# ATSAM3SD8B register map
Vendor: Atmel; File version: 0
CPU: CM3 r2p0, selectable endian, no MPU, no FPU, 0x4 interrupt priority bits, 0x0 interrupts
Registers are 32-bit, read-write, no defined reset value unless marked. A register's access mark holds for its fields unless they carry their own. Offsets are from the block's base; [hi:lo] are bit positions; {n}, {i} and the like mark numbered series; 'fields as' and 'values as' point back to an identical list.

## CRCCU — Cyclic Redundancy Check Calculation Unit
Base 0x40044000; register names take the prefix CRCCU_
0x00 DSCR reset 0x0 — CRCCU Descriptor Base Register
  [31:9] DSCR — Descriptor Base Address
0x08 DMA_EN wo reset 0x0 — CRCCU DMA Enable Register
  [0] DMAEN — DMA Enable Register
0x0C DMA_DIS wo reset 0x0 — CRCCU DMA Disable Register
  [0] DMADIS — DMA Disable Register
0x10 DMA_SR ro reset 0x0 — CRCCU DMA Status Register
  [0] DMASR — DMA Status Register
0x14 DMA_IER wo reset 0x0 — CRCCU DMA Interrupt Enable Register
  [0] DMAIER — Interrupt Enable register
0x18 DMA_IDR wo reset 0x0 — CRCCU DMA Interrupt Disable Register
  [0] DMAIDR — Interrupt Disable register
0x1C DMA_IMR ro reset 0x0 — CRCCU DMA Interrupt Mask Register
  [0] DMAIMR — Interrupt Mask Register
0x20 DMA_ISR ro reset 0x0 — CRCCU DMA Interrupt Status Register
  [0] DMAISR — Interrupt Status register
0x34 CR wo reset 0x0 — CRCCU Control Register
  [0] RESET — CRC Computation Reset
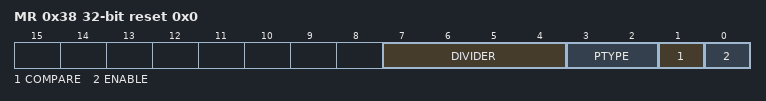
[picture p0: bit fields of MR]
0x38 MR reset 0x0 — CRCCU Mode Register
  [7:4] DIVIDER — Request Divider
  [3:2] PTYPE — Primitive Polynomial
    0=CCITT8023 (Polynom 0x04C11DB7); 1=CASTAGNOLI (Polynom 0x1EDC6F41); 2=CCITT16 (Polynom 0x1021)
  [1] COMPARE — CRC Compare
  [0] ENABLE — CRC Enable
0x3C SR ro reset 0xFFFFFFFF — CRCCU Status Register
  [31:0] CRC — Cyclic Redundancy Check Value
0x40 IER wo reset 0x0 — CRCCU Interrupt Enable Register
  [0] ERRIER — CRC Error Interrupt Enable
0x44 IDR wo reset 0x0 — CRCCU Interrupt Disable Register
  [0] ERRIDR — CRC Error Interrupt Disable
0x48 IMR ro reset 0x0 — CRCCU Interrupt Mask Register
  [0] ERRIMR — CRC Error Interrupt Mask
0x4C ISR ro reset 0x0 — CRCCU Interrupt Status Register
  [0] ERRISR — CRC Error Interrupt Status

## MATRIX — AHB Bus Matrix
Base 0x400E0200
{0x0+4i} MATRIX_MCFG[{i}] (i=0..3) — Master Configuration Register
  [2:0] ULBT — Undefined Length Burst Type
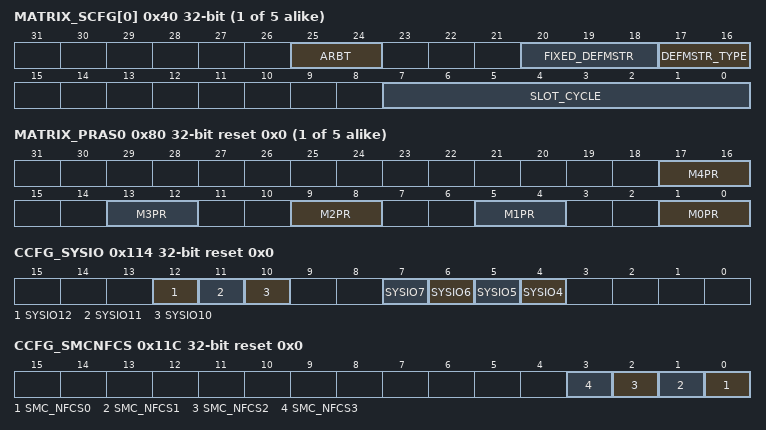
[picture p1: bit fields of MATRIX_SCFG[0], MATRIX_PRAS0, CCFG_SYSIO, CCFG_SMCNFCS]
{0x40+4i} MATRIX_SCFG[{i}] (i=0..4) — Slave Configuration Register
  [25:24] ARBT — Arbitration Type
  [20:18] FIXED_DEFMSTR — Fixed Default Master
  [17:16] DEFMSTR_TYPE — Default Master Type
  [7:0] SLOT_CYCLE — Maximum Number of Allowed Cycles for a Burst
{0x80+8i} MATRIX_PRAS{i} reset 0x0 (i=0..4) — Priority Register A for Slave {i}
  [4n+1:4n] M{n}PR (n=0..4) — Master {n} Priority
0x114 CCFG_SYSIO reset 0x0 — System I/O Configuration register
  [12] SYSIO12 — PB12 or ERASE Assignment
  [11] SYSIO11 — PB11 or DDP Assignment
  [10] SYSIO10 — PB10 or DDM Assignment
  [7] SYSIO7 — PB7 or TCK/SWCLK Assignment
  [6] SYSIO6 — PB6 or TMS/SWDIO Assignment
  [5] SYSIO5 — PB5 or TDO/TRACESWO Assignment
  [4] SYSIO4 — PB4 or TDI Assignment
0x11C CCFG_SMCNFCS reset 0x0 — SMC Chip Select NAND Flash Assignment Register
  [n] SMC_NFCS{n} (n=0..3) — SMC NAND Flash Chip Select {n} Assignment
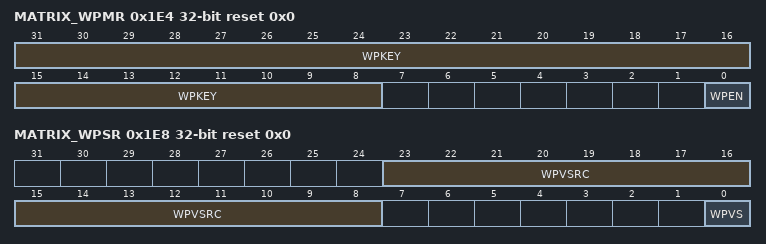
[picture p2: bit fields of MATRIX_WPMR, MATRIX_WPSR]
0x1E4 MATRIX_WPMR reset 0x0 — Write Protect Mode Register
  [31:8] WPKEY — Write Protect KEY (Write-only)
  [0] WPEN — Write Protect ENable
0x1E8 MATRIX_WPSR ro reset 0x0 — Write Protect Status Register
  [23:8] WPVSRC — Write Protect Violation Source
  [0] WPVS — Write Protect Violation Status

## CHIPID — Chip Identifier
Base 0x400E0740; register names take the prefix CHIPID_
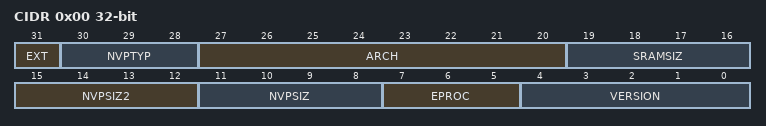
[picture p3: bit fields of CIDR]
0x00 CIDR ro — Chip ID Register
  [31] EXT — Extension Flag
  [30:28] NVPTYP — Nonvolatile Program Memory Type
    0=ROM; 1=ROMLESS (ROMless or on-chip Flash); 2=FLASH (Embedded Flash Memory); 3=ROM_FLASH (ROM and Embedded Flash MemoryNVPSIZ is ROM size NVPSIZ2 is Flash size); 4=SRAM (SRAM emulating ROM)
  [27:20] ARCH — Architecture Identifier
    25=AT91SAM9xx Series; 41=AT91SAM9XExx Series; 52=AT91x34 Series; 55=CAP7 (CAP7 Series); 57=CAP9 (CAP9 Series); 59=CAP11 (CAP11 Series); 64=AT91x40 Series; 66=AT91x42 Series; 85=AT91x55 Series; 96=AT91SAM7Axx Series; 97=AT91SAM7AQxx Series; 99=AT91x63 Series; 112=AT91SAM7Sxx Series; 113=AT91SAM7XCxx Series; 114=AT91SAM7SExx Series; 115=AT91SAM7Lxx Series; 117=AT91SAM7Xxx Series; 118=AT91SAM7SLxx Series; 128=SAM3UxC Series (100-pin version); 129=SAM3UxE Series (144-pin version); 131=SAM3AxC Series (100-pin version); 131=SAM4AxC Series (100-pin version); 132=SAM3XxC Series (100-pin version); 132=SAM4XxC Series (100-pin version); 133=SAM3XxE Series (144-pin version); 133=SAM4XxE Series (144-pin version); 134=SAM3XxG Series (208/217-pin version); 134=SAM4XxG Series (208/217-pin version); 136=SAM3SxASeries (48-pin version); 136=SAM4SxA Series (48-pin version); 137=SAM3SxB Series (64-pin version); 137=SAM4SxB Series (64-pin version); 138=SAM3SxC Series (100-pin version); 138=SAM4SxC Series (100-pin version); 146=AT91x92 Series; 147=SAM3NxA Series (48-pin version); 148=SAM3NxB Series (64-pin version); 149=SAM3NxC Series (100-pin version); 153=SAM3SDxB Series (64-pin version); 154=SAM3SDxC Series (100-pin version); 165=SAM5A; 240=AT75Cxx Series
  [19:16] SRAMSIZ — Internal SRAM Size
    0=48K (48K bytes); 1=1K (1K bytes); 2=2K (2K bytes); 3=6K (6K bytes); 4=24K (24K bytes); 5=4K (4K bytes); 6=80K (80K bytes); 7=160K (160K bytes); 8=8K (8K bytes); 9=16K (16K bytes); 10=32K (32K bytes); 11=64K (64K bytes); 12=128K (128K bytes); 13=256K (256K bytes); 14=96K (96K bytes); 15=512K (512K bytes)
  [15:12] NVPSIZ2 — Second Nonvolatile Program Memory Size
    0=NONE; 1=8K (8K bytes); 2=16K (16K bytes); 3=32K (32K bytes); 5=64K (64K bytes); 7=128K (128K bytes); 9=256K (256K bytes); 10=512K (512K bytes); 12=1024K (1024K bytes); 14=2048K (2048K bytes)
  [11:8] NVPSIZ — Nonvolatile Program Memory Size
    values as NVPSIZ2
  [7:5] EPROC — Embedded Processor
    1=ARM946ES; 2=ARM7TDMI; 3=CM3 (Cortex-M3); 4=ARM920T; 5=ARM926EJS; 6=CA5 (Cortex-A5); 7=CM4 (Cortex-M4)
  [4:0] VERSION — Version of the Device
0x04 EXID ro — Chip ID Extension Register
  [31:0] EXID — Chip ID Extension

## EFC — Embedded Flash Controller
Base 0x400E0A00; register names take the prefix EFC_
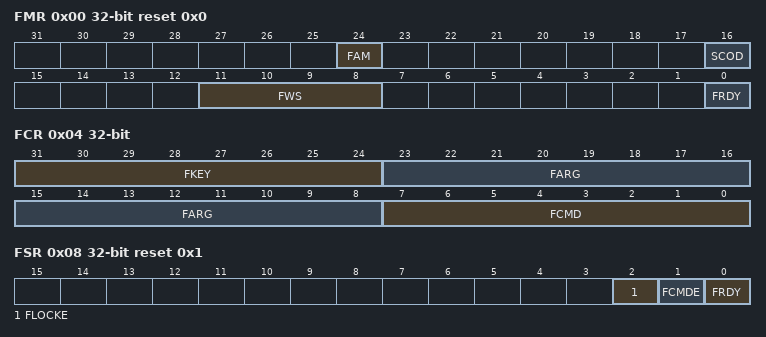
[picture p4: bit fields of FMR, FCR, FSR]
0x00 FMR reset 0x0 — EEFC Flash Mode Register
  [24] FAM — Flash Access Mode
  [16] SCOD — Sequential Code Optimization Disable
  [11:8] FWS — Flash Wait State
  [0] FRDY — Ready Interrupt Enable
0x04 FCR wo — EEFC Flash Command Register
  [31:24] FKEY — Flash Writing Protection Key
    90=PASSWD (The 0x5A value enables the command defined by the bits of the register. If the field is written with a different value, the write is not performed and no action is started.)
  [23:8] FARG — Flash Command Argument
  [7:0] FCMD — Flash Command
    0=GETD (Get Flash Descriptor); 1=WP (Write page); 2=WPL (Write page and lock); 3=EWP (Erase page and write page); 4=EWPL (Erase page and write page then lock); 5=EA (Erase all); 8=SLB (Set Lock Bit); 9=CLB (Clear Lock Bit); 10=GLB (Get Lock Bit); 11=SGPB (Set GPNVM Bit); 12=CGPB (Clear GPNVM Bit); 13=GGPB (Get GPNVM Bit); 14=STUI (Start Read Unique Identifier); 15=SPUI (Stop Read Unique Identifier)
0x08 FSR ro reset 0x1 — EEFC Flash Status Register
  [2] FLOCKE — Flash Lock Error Status
  [1] FCMDE — Flash Command Error Status
  [0] FRDY — Flash Ready Status
0x0C FRR ro reset 0x0 — EEFC Flash Result Register
  [31:0] FVALUE — Flash Result Value

## RSTC — Reset Controller
Base 0x400E1400; register names take the prefix RSTC_
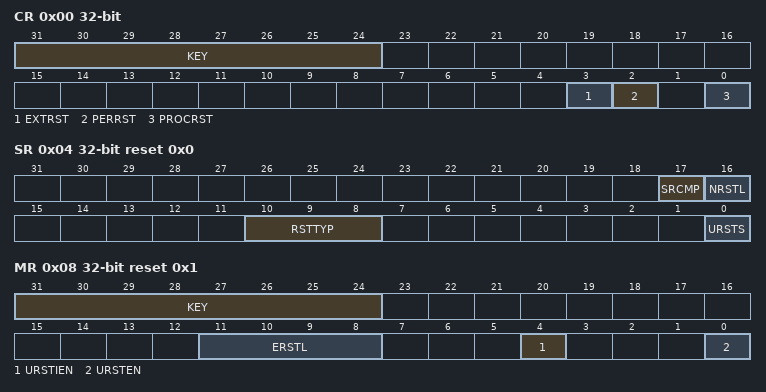
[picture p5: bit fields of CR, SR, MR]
0x00 CR wo — Control Register
  [31:24] KEY — System Reset Key
  [3] EXTRST — External Reset
  [2] PERRST — Peripheral Reset
  [0] PROCRST — Processor Reset
0x04 SR ro reset 0x0 — Status Register
  [17] SRCMP — Software Reset Command in Progress
  [16] NRSTL — NRST Pin Level
  [10:8] RSTTYP — Reset Type
  [0] URSTS — User Reset Status
0x08 MR reset 0x1 — Mode Register
  [31:24] KEY — Password
  [11:8] ERSTL — External Reset Length
  [4] URSTIEN — User Reset Interrupt Enable
  [0] URSTEN — User Reset Enable

## RTT — Real-time Timer
Base 0x400E1430; register names take the prefix RTT_
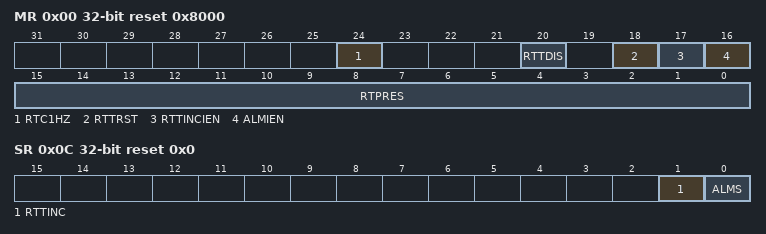
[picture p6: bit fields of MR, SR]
0x00 MR reset 0x8000 — Mode Register
  [24] RTC1HZ — Real-Time Clock 1Hz Clock Selection
  [20] RTTDIS — Real-time Timer Disable
  [18] RTTRST — Real-time Timer Restart
  [17] RTTINCIEN — Real-time Timer Increment Interrupt Enable
  [16] ALMIEN — Alarm Interrupt Enable
  [15:0] RTPRES — Real-time Timer Prescaler Value
0x04 AR reset 0xFFFFFFFF — Alarm Register
  [31:0] ALMV — Alarm Value
0x08 VR ro reset 0x0 — Value Register
  [31:0] CRTV — Current Real-time Value
0x0C SR ro reset 0x0 — Status Register
  [1] RTTINC — Real-time Timer Increment
  [0] ALMS — Real-time Alarm Status

## WDT — Watchdog Timer
Base 0x400E1450; register names take the prefix WDT_
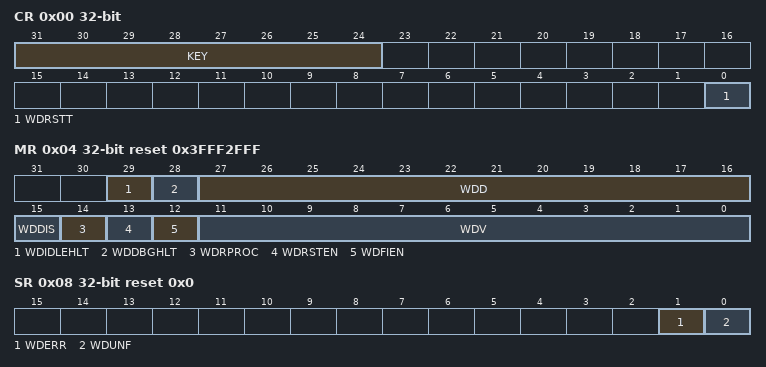
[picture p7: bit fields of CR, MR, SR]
0x00 CR wo — Control Register
  [31:24] KEY — Password
  [0] WDRSTT — Watchdog Restart
0x04 MR reset 0x3FFF2FFF — Mode Register
  [29] WDIDLEHLT — Watchdog Idle Halt
  [28] WDDBGHLT — Watchdog Debug Halt
  [27:16] WDD — Watchdog Delta Value
  [15] WDDIS — Watchdog Disable
  [14] WDRPROC — Watchdog Reset Processor
  [13] WDRSTEN — Watchdog Reset Enable
  [12] WDFIEN — Watchdog Fault Interrupt Enable
  [11:0] WDV — Watchdog Counter Value
0x08 SR ro reset 0x0 — Status Register
  [1] WDERR — Watchdog Error
  [0] WDUNF — Watchdog Underflow

## GPBR — General Purpose Backup Register
Base 0x400E1490; register names take the prefix GPBR_
{0x0+4i} GPBR[{i}] (i=0..7) — General Purpose Backup Register
  [31:0] GPBR_VALUE — Value of GPBR x
